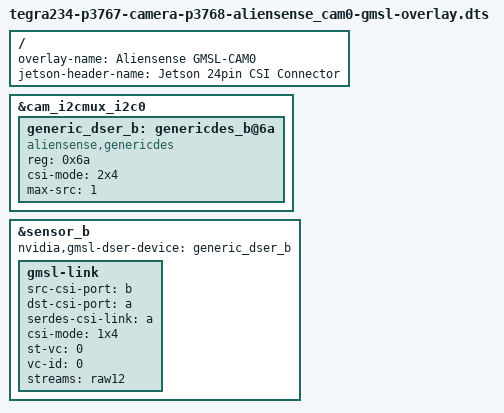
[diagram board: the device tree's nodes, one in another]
// SPDX-License-Identifier: GPL-2.0-only OR MIT
/*
 * Copyright (c) 2026 Aliensense
 *
 * tegra234-p3767-camera-p3768-aliensense_cam0-gmsl-overlay.dts
 */

/dts-v1/;
/plugin/;

#include <dt-bindings/clock/tegra234-clock.h>
#include <dt-bindings/gpio/tegra234-gpio.h>
#include <dt-bindings/tegra234-p3767-0000-common.h>


/ {
	overlay-name = "Aliensense GMSL-CAM0";
	jetson-header-name = "Jetson 24pin CSI Connector";
	compatible = JETSON_COMPATIBLE_P3768;

	fragment@0 {
		target = <&cam_i2cmux_i2c0>;
		__overlay__ {
			generic_dser_b: genericdes_b@6a {
				compatible = "aliensense,genericdes";
				reg = <0x6a>;
				csi-mode = "2x4";
				max-src = <1>;
			};
		};
	};

	fragment@1 {
		target = <&sensor_b>;
		__overlay__ {
			nvidia,gmsl-dser-device = <&generic_dser_b>;
			gmsl-link {
				src-csi-port = "b";
				dst-csi-port = "a";
				serdes-csi-link = "a";
				csi-mode = "1x4";
				st-vc = <0>;
				vc-id = <0>;
				streams = "raw12";
			};
		};
	};

};
